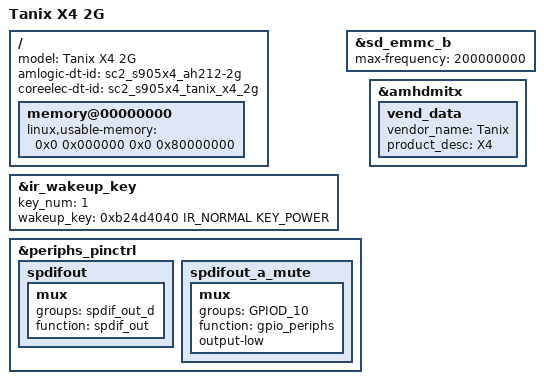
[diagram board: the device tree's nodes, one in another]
#include "sc2_s905x4_2g.dts"

/ {
	model = "Tanix X4 2G";
	amlogic-dt-id = "sc2_s905x4_ah212-2g";
	coreelec-dt-id = "sc2_s905x4_tanix_x4_2g";

	memory@00000000 {
		linux,usable-memory = <0x0 0x000000 0x0 0x80000000>;
	};
};

&ir_wakeup_key {
	key_num = <1>;
	wakeup_key = <0xb24d4040 IR_NORMAL KEY_POWER>;
};

/* The Tanix X4 android dump uses 200 MHz for the SD card interface */
&sd_emmc_b {
	max-frequency = <200000000>;
};

&periphs_pinctrl {
	spdifout: spdifout {
		mux {
			groups = "spdif_out_d";
			function = "spdif_out";
		};
	};

	spdifout_a_mute: spdifout_a_mute {
		mux {
			groups = "GPIOD_10";
			function = "gpio_periphs";
			output-low;
		};
	};
};

&amhdmitx {
	vend_data {
		vendor_name = "Tanix";
		product_desc = "X4";
	};
};
